# mpu register map
Vendor: Texas Instruments
Peripheral module from a debugger description file (folder Keystone2).
Registers are 32-bit, read-write, no defined reset value unless marked. A register's access mark holds for its fields unless they carry their own. Offsets are as the file gives them; lines under a group give offsets from that group; [hi:lo] are bit positions; {n}, {i} and the like mark numbered series; 'fields as' and 'values as' point back to an identical list; <NAME> marks a mode.

## MPU_14
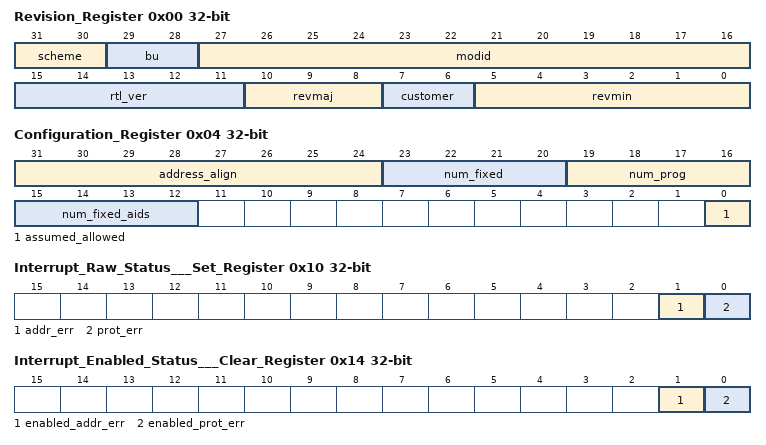
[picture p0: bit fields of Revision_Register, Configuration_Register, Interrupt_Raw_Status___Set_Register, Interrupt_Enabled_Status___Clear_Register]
0x00 Revision_Register ro
  [31:30] scheme
  [29:28] bu — Business Unit
  [27:16] modid — The MODID field specifies the module ID for the module.
  [15:11] rtl_ver — RTL Version identifies the version of the RTL.
  [10:8] revmaj — Major Version field specifies the major revision for the module.
  [7:6] customer
  [5:0] revmin — Minor Version field specifies the minor revision for the module.
0x04 Configuration_Register ro
  [31:24] address_align — Address alignment for range checking: 0=1k, 1=2k, 2=4k, etc.
  [23:20] num_fixed — Number of fixed address ranges: configurable as 0 or 1
  [19:16] num_prog — Number of programmable address ranges: value is determined by configuration
  [15:12] num_fixed_aids — Number of supported AIDs
  [0] assumed_allowed — Assumed allowed mode
0x10 Interrupt_Raw_Status___Set_Register
  [1] addr_err — Addressing violation error. Raw status is read. Write a 1 to set the status.
  [0] prot_err — Protection violation error. Raw status is read. Write a 1 to set the status.
0x14 Interrupt_Enabled_Status___Clear_Register
  [1] enabled_addr_err — Addressing violation error. Enabled status is read. Write a 1 to clear the status.
  [0] enabled_prot_err — Protection violation error. Enabled status is read. Write a 1 to clear the status.
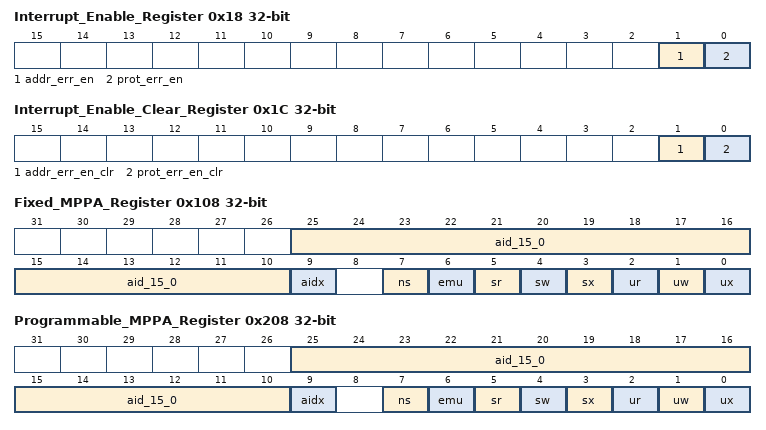
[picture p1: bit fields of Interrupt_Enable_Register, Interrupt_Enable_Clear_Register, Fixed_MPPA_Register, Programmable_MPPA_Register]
0x18 Interrupt_Enable_Register
  [1] addr_err_en — Addressing violation error enable. Write a 1 to set the enable.
  [0] prot_err_en — Protection violation error enable. Write a 1 to set the enable.
0x1C Interrupt_Enable_Clear_Register
  [1] addr_err_en_clr — Addressing violation error enable. Write a 1 to clear the enable.
  [0] prot_err_en_clr — Protection violation error enable. Write a 1 to clear the enable.
0x20 EOI_Register
  [7:0] eoi_vector — EOI vector value
0x24 Interrupt_Vector_Register ro
  [31:0] intr_vec — Interrupt vector
0x100 Fixed_Start_Address_Register ro
  [31:0] start_addr — Start address for the fixed region
0x104 Fixed_End_Address_Register ro
  [31:0] end_addr — End address for the fixed region
0x108 Fixed_MPPA_Register
  [25:10] aid_15_0 — AIDs enabled for this region. Defaults to input value.
  [9] aidx — Additional AIDs enabled. Defaults to input value.
  [7] ns — Non-secure permission. Defaults to input value.
  [6] emu — Debug permission. Defaults to input value.
  [5] sr — Supervisor read permission. Defaults to input value.
  [4] sw — Supervisor write permission. Defaults to input value.
  [3] sx — Supervisor executable permission. Defaults to input value.
  [2] ur — User read permission. Defaults to input value.
  [1] uw — User write permission. Defaults to input value.
  [0] ux — User executable permission. Defaults to input value.
0x200 Programmable_Start_Address_Register — (1 of 16, stride 16)
  [31:0] start_addr — Start address for a programmable region
0x204 Programmable_End_Address_Register — (1 of 16, stride 16)
  [31:0] end_addr — End address for a programmable region
0x208 Programmable_MPPA_Register — (1 of 16, stride 16)
  fields as Fixed_MPPA_Register
0x300 Fault_Address_Register ro
  [31:0] fault_addr — Fault address
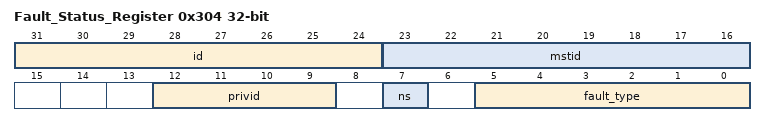
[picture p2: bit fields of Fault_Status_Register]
0x304 Fault_Status_Register ro
  [31:24] id — Transfer ID
  [23:16] mstid — Master ID
  [12:9] privid — Privilege ID
  [7] ns — Non-secure access
  [5:0] fault_type
0x308 Fault_Clear_Register wo
  [0] fault_clr — Fault clear. Writing a 1 clears the current fault.
